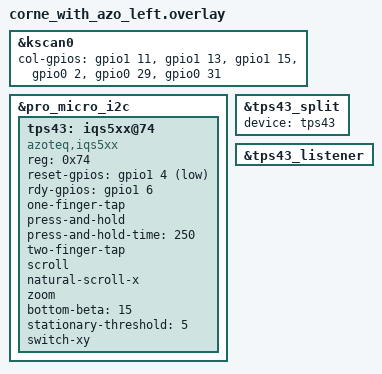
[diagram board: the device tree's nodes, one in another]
#include "corne_with_azo.dtsi"

&kscan0 {
    col-gpios
        = <&gpio1 11 GPIO_ACTIVE_HIGH>
        , <&gpio1 13 GPIO_ACTIVE_HIGH>
        , <&gpio1 15 GPIO_ACTIVE_HIGH>
        , <&gpio0 2  GPIO_ACTIVE_HIGH>
        , <&gpio0 29 GPIO_ACTIVE_HIGH>
        , <&gpio0 31 GPIO_ACTIVE_HIGH>
        ;
};

&pro_micro_i2c {
    status = "okay";
    tps43: iqs5xx@74 {
        status = "okay";
        compatible = "azoteq,iqs5xx";
        reg = <0x74>;

        reset-gpios = <&gpio1 4 GPIO_ACTIVE_LOW>;
        rdy-gpios = <&gpio1 6 GPIO_ACTIVE_HIGH>;

        /*
         * Potentially non-exhaustive list of configuration options.
         * See: dts/bindings/input/azoteq,iqs5xx-common.yaml for a full list.
         */
        one-finger-tap;
        press-and-hold;
        press-and-hold-time = <250>;
        two-finger-tap;

        scroll;
        natural-scroll-x;

        zoom;

        bottom-beta = <15>;
        stationary-threshold = <5>;

        switch-xy;
    };
};

&tps43_split {
    device = <&tps43>;

};

&tps43_listener {
    status = "okay";
};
